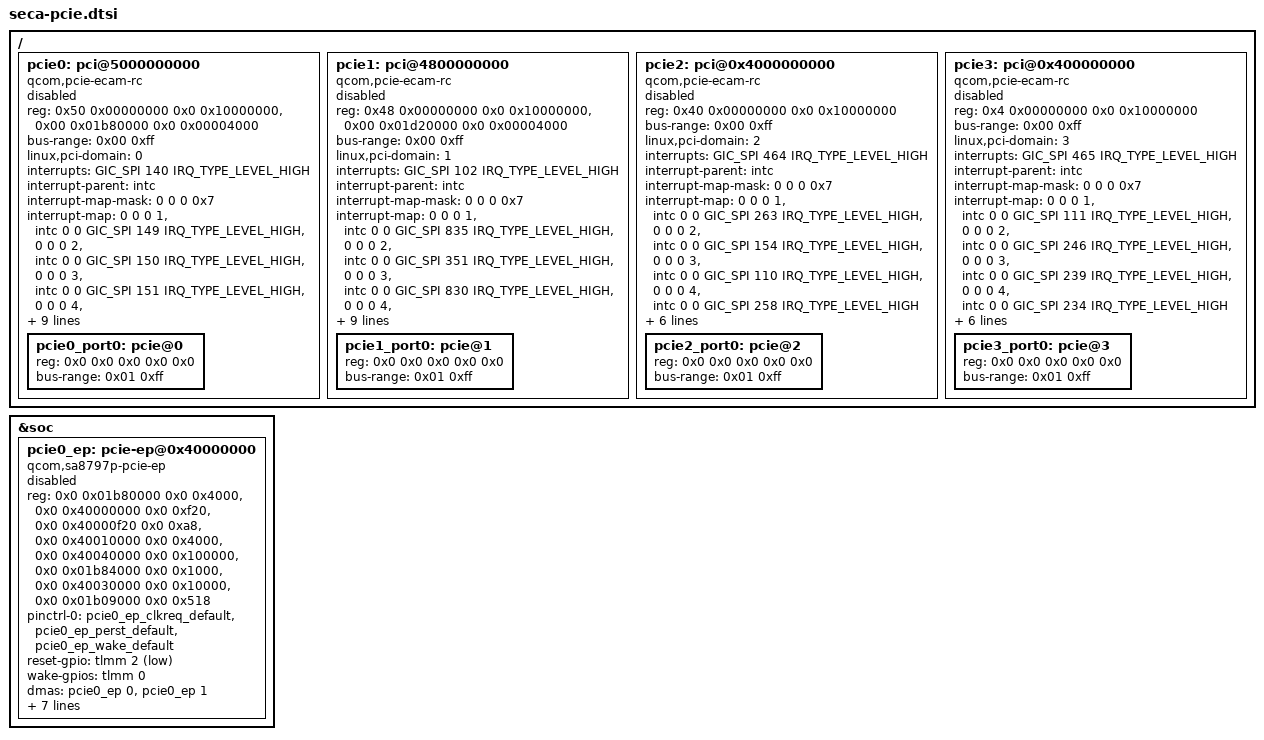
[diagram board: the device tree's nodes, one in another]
// SPDX-License-Identifier: BSD-3-Clause
/*
 * Copyright (c) Qualcomm Technologies, Inc. and/or its subsidiaries.
 */

/ {
	pcie0: pci@5000000000 {
		compatible = "qcom,pcie-ecam-rc";
		reg = <0x50 0x00000000 0x0 0x10000000>,
		      <0x00 0x01b80000 0x0 0x00004000>;
		reg-names = "dbi", "parf";

		device_type = "pci";

		#address-cells = <3>;
		#size-cells = <2>;

		ranges = <0x01000000 0x0 0x40000000 0x0 0x40000000 0x0 0x100000>,
			<0x02000000 0x0 0x40100000 0x0 0x40100000 0x0 0x7000000>,
			<0x43000000 0x50 0x10100000 0x50 0x10100000 0x8 0x00000000>;
		bus-range = <0x00 0xff>;

		linux,pci-domain = <0>;

		interrupts = <GIC_SPI 140 IRQ_TYPE_LEVEL_HIGH>;
		interrupt-names = "global_int";

		interrupt-parent = <&intc>;
		#interrupt-cells = <1>;
		interrupt-map-mask = <0 0 0 0x7>;
		interrupt-map = <0 0 0 1 &intc 0 0 GIC_SPI 149 IRQ_TYPE_LEVEL_HIGH>, //INTa
					<0 0 0 2 &intc 0 0 GIC_SPI 150 IRQ_TYPE_LEVEL_HIGH>, //INTb
					<0 0 0 3 &intc 0 0 GIC_SPI 151 IRQ_TYPE_LEVEL_HIGH>, //INTc
					<0 0 0 4 &intc 0 0 GIC_SPI 152 IRQ_TYPE_LEVEL_HIGH>; //INTd

		dma-coherent;
		iommu-map = <0x0 &pcie_smmu 0x0000 0x1>,
				<0x100 &pcie_smmu 0x0100 0x1>,
				<0x200 &pcie_smmu 0x0200 0x1>,
				<0x300 &pcie_smmu 0x0300 0x1>;

		rasdp-off = <0x39C>;
		safety-supported;

		msi-map = <0x0 &gic_its 0x80000 0x10000>;

		status = "disabled";

		pcie0_port0: pcie@0 {
				device_type = "pci";
				reg = <0x0 0x0 0x0 0x0 0x0>;
				bus-range = <0x01 0xff>;
				#address-cells = <3>;
				#size-cells = <2>;
				ranges;
		};
	};

	pcie1: pci@4800000000 {
		compatible = "qcom,pcie-ecam-rc";
		reg = <0x48 0x00000000 0x0 0x10000000>,
		      <0x00 0x01d20000 0x0 0x00004000>;
		reg-names = "dbi", "parf";

		device_type = "pci";

		#address-cells = <3>;
		#size-cells = <2>;

		ranges = <0x01000000 0x0 0x50000000 0x0 0x50000000 0x0 0x100000>,
			<0x02000000 0x0 0x50100000 0x0 0x50100000 0x0 0x7000000>,
			<0x43000000 0x48 0x10100000 0x48 0x10100000 0x4 0x00000000>;
		bus-range = <0x00 0xff>;

		linux,pci-domain = <1>;

		interrupts = <GIC_SPI 102 IRQ_TYPE_LEVEL_HIGH>;
		interrupt-names = "global_int";

		interrupt-parent = <&intc>;
		#interrupt-cells = <1>;
		interrupt-map-mask = <0 0 0 0x7>;
		interrupt-map = <0 0 0 1 &intc 0 0 GIC_SPI 835 IRQ_TYPE_LEVEL_HIGH>, //INTa
					<0 0 0 2 &intc 0 0 GIC_SPI 351 IRQ_TYPE_LEVEL_HIGH>, //INTb
					<0 0 0 3 &intc 0 0 GIC_SPI 830 IRQ_TYPE_LEVEL_HIGH>, //INTc
					<0 0 0 4 &intc 0 0 GIC_SPI 348 IRQ_TYPE_LEVEL_HIGH>; //INTd

		rasdp-off = <0x39C>;
		safety-supported;

		msi-map = <0x0 &gic_its 0x90000 0x10000>;

		dma-coherent;
		iommu-map = <0x0 &pcie_smmu 0x10000 0x1>,
				<0x100 &pcie_smmu 0x10100 0x1>,
				<0x200 &pcie_smmu 0x10200 0x1>,
				<0x300 &pcie_smmu 0x10300 0x1>;

		status = "disabled";

		pcie1_port0: pcie@1 {
				device_type = "pci";
				reg = <0x0 0x0 0x0 0x0 0x0>;
				bus-range = <0x01 0xff>;
				#address-cells = <3>;
				#size-cells = <2>;
				ranges;
		};
	};

	pcie2: pci@0x4000000000 {
		compatible = "qcom,pcie-ecam-rc";
		reg = <0x40 0x00000000 0x0 0x10000000>;

		device_type = "pci";

		#address-cells = <3>;
		#size-cells = <2>;

		ranges = <0x01000000 0x0 0x60000000 0x0 0x60000000 0x0 0x100000>,
			<0x02000000 0x0 0x60100000 0x0 0x60100000 0x0 0x7000000>,
			<0x43000000 0x40 0x10100000 0x40 0x10100000 0x4 0x00000000>;
		bus-range = <0x00 0xff>;

		linux,pci-domain = <2>;

		interrupts = <GIC_SPI 464 IRQ_TYPE_LEVEL_HIGH>;
		interrupt-names = "global_int";

		interrupt-parent = <&intc>;
		#interrupt-cells = <1>;
		interrupt-map-mask = <0 0 0 0x7>;
		interrupt-map = <0 0 0 1 &intc 0 0 GIC_SPI 263 IRQ_TYPE_LEVEL_HIGH>, //INTa
					<0 0 0 2 &intc 0 0 GIC_SPI 154 IRQ_TYPE_LEVEL_HIGH>, //INTb
					<0 0 0 3 &intc 0 0 GIC_SPI 110 IRQ_TYPE_LEVEL_HIGH>, //INTc
					<0 0 0 4 &intc 0 0 GIC_SPI 258 IRQ_TYPE_LEVEL_HIGH>; //INTd

		msi-map = <0x0 &gic_its 0xa0000 0x10000>;

		dma-coherent;
		iommu-map = <0x0 &pcie_smmu 0x20000 0x1>,
				<0x100 &pcie_smmu 0x20100 0x1>,
				<0x200 &pcie_smmu 0x20200 0x1>,
				<0x300 &pcie_smmu 0x20300 0x1>;

		status = "disabled";

		pcie2_port0: pcie@2 {
				device_type = "pci";
				reg = <0x0 0x0 0x0 0x0 0x0>;
				bus-range = <0x01 0xff>;
				#address-cells = <3>;
				#size-cells = <2>;
				ranges;
		};
	};

	pcie3: pci@0x400000000 {
		compatible = "qcom,pcie-ecam-rc";
		reg = <0x4 0x00000000 0x0 0x10000000>;

		device_type = "pci";

		#address-cells = <3>;
		#size-cells = <2>;

		ranges = <0x01000000 0x0 0x70000000 0x0 0x70000000 0x0 0x100000>,
			<0x02000000 0x0 0x70100000 0x0 0x70100000 0x0 0x7000000>,
			<0x43000000 0x4 0x10100000 0x4 0x10100000 0x0 0x80000000>;
		bus-range = <0x00 0xff>;

		linux,pci-domain = <3>;

		interrupts = <GIC_SPI 465 IRQ_TYPE_LEVEL_HIGH>;
		interrupt-names = "global_int";

		interrupt-parent = <&intc>;
		#interrupt-cells = <1>;
		interrupt-map-mask = <0 0 0 0x7>;
		interrupt-map = <0 0 0 1 &intc 0 0 GIC_SPI 111 IRQ_TYPE_LEVEL_HIGH>, //INTa
					<0 0 0 2 &intc 0 0 GIC_SPI 246 IRQ_TYPE_LEVEL_HIGH>, //INTb
					<0 0 0 3 &intc 0 0 GIC_SPI 239 IRQ_TYPE_LEVEL_HIGH>, //INTc
					<0 0 0 4 &intc 0 0 GIC_SPI 234 IRQ_TYPE_LEVEL_HIGH>; //INTd

		msi-map = <0x0 &gic_its 0xb0000 0x10000>;

		dma-coherent;
		iommu-map = <0x0 &pcie_smmu 0x30000 0x1>,
				<0x100 &pcie_smmu 0x30100 0x1>,
				<0x200 &pcie_smmu 0x30200 0x1>,
				<0x300 &pcie_smmu 0x30300 0x1>;

		status = "disabled";

		pcie3_port0: pcie@3 {
				device_type = "pci";
				reg = <0x0 0x0 0x0 0x0 0x0>;
				bus-range = <0x01 0xff>;
				#address-cells = <3>;
				#size-cells = <2>;
				ranges;
		};
	};
};

&soc {
	pcie0_ep: pcie-ep@0x40000000 {
		compatible = "qcom,sa8797p-pcie-ep";
		reg = <0x0 0x01b80000 0x0 0x4000>,
		      <0x0 0x40000000 0x0 0xf20>,
		      <0x0 0x40000f20 0x0 0xa8>,
		      <0x0 0x40010000 0x0 0x4000>,
		      <0x0 0x40040000 0x0 0x100000>,
		      <0x0 0x01b84000 0x0 0x1000>,
		      <0x0 0x40030000 0x0 0x10000>,
		      <0x0 0x01b09000 0x0 0x518>;
		reg-names = "parf", "dbi", "elbi", "atu", "addr_space",
			    "mmio", "dma", "phy_pcs";

		pinctrl-names = "default";
		pinctrl-0 = <&pcie0_ep_clkreq_default &pcie0_ep_perst_default
				&pcie0_ep_wake_default>;

		reset-gpio = <&tlmm 2 GPIO_ACTIVE_LOW>;
		wake-gpios = <&tlmm 0 GPIO_ACTIVE_HIGH>;

		#dma-cells = <1>;
		dmas = <&pcie0_ep 0>, <&pcie0_ep 1>;
		dma-names = "rx", "tx";

		interrupts = <GIC_SPI 140 IRQ_TYPE_LEVEL_HIGH>,
			     <GIC_SPI 153 IRQ_TYPE_LEVEL_HIGH>,
			     <GIC_SPI 443 IRQ_TYPE_LEVEL_HIGH>;
		interrupt-names = "global", "doorbell", "dma";

		dma-coherent;
		iommus = <&pcie_smmu 0x0>,
			<&pcie_smmu 0x1>;

		max-link-speed = <4>;
		num-lanes = <8>;

		status = "disabled";
	};
};
